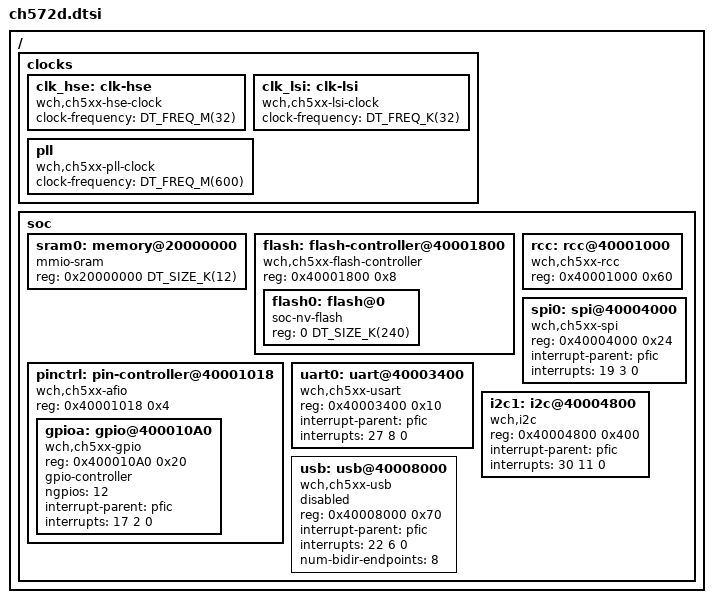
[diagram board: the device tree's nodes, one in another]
/*
 * Copyright (c) 2024 Michael Hope
 * Copyright (c) 2024 Paul Wedeck <paulwedeck@gmail.com>
 *
 * SPDX-License-Identifier: Apache-2.0
 */

#include <freq.h>
#include <mem.h>
#include <wch/qingke-v3c.dtsi>
#include <zephyr/dt-bindings/gpio/gpio.h>
#include <zephyr/dt-bindings/i2c/i2c.h>
#include <zephyr/dt-bindings/clock/ch5xx-clocks.h>

/ {
	clocks {
		clk_hse: clk-hse {
			#clock-cells = <0>;
			compatible = "wch,ch5xx-hse-clock";
			status = "okay";
			clock-frequency = <DT_FREQ_M(32)>;
		};

		clk_lsi: clk-lsi {
			#clock-cells = <0>;
			compatible = "wch,ch5xx-lsi-clock";
			status = "okay";
			/* 24 - 40 thus using 32 */
			clock-frequency = <DT_FREQ_K(32)>;
		};

		pll: pll {
			#clock-cells = <0>;
			compatible = "wch,ch5xx-pll-clock";
			status = "okay";
			clock-frequency = <DT_FREQ_M(600)>;
		};
	};

	soc {
		sram0: memory@20000000 {
			compatible = "mmio-sram";
			reg = <0x20000000 DT_SIZE_K(12)>;
		};

		flash: flash-controller@40001800 {
			compatible = "wch,ch5xx-flash-controller";
			reg = <0x40001800 0x8>;

			#address-cells = <1>;
			#size-cells = <1>;

			flash0: flash@0 {
				compatible = "soc-nv-flash";
				reg = <0 DT_SIZE_K(240)>;
			};
		};

		rcc: rcc@40001000 {
			compatible = "wch,ch5xx-rcc";
			reg = <0x40001000 0x60>;
			#clock-cells = <1>;
			status = "okay";
		};

		pinctrl: pin-controller@40001018 {
			compatible = "wch,ch5xx-afio";
			reg = <0x40001018 0x4>;
			#address-cells = <1>;
			#size-cells = <1>;
			status = "okay";

			gpioa: gpio@400010A0 {
				compatible = "wch,ch5xx-gpio";
				reg = <0x400010A0 0x20>;
				gpio-controller;
				#gpio-cells = <2>;
				ngpios = <12>;
				interrupt-parent = <&pfic>;
				interrupts = <17 2 0>;
			};
		};

		spi0: spi@40004000 {
			compatible = "wch,ch5xx-spi";
			reg = <0x40004000 0x24>;
			interrupt-parent = <&pfic>;
			interrupts = <19 3 0>;
			#address-cells = <1>;
			#size-cells = <0>;
		};

		uart0: uart@40003400 {
			compatible = "wch,ch5xx-usart";
			reg = <0x40003400 0x10>;
			interrupt-parent = <&pfic>;
			interrupts = <27 8 0>;
		};

		i2c1: i2c@40004800 {
			compatible = "wch,i2c";
			#address-cells = <1>;
			#size-cells = <0>;
			reg = <0x40004800 0x400>;
			interrupt-parent = <&pfic>;
			interrupts = <30 11 0>;
		};

		usb: usb@40008000 {
			compatible = "wch,ch5xx-usb";
			reg = <0x40008000 0x70>;
			interrupt-parent = <&pfic>;
			interrupts = <22 6 0>;
			num-bidir-endpoints = <8>;
			status = "disabled";
		};
	};
};
